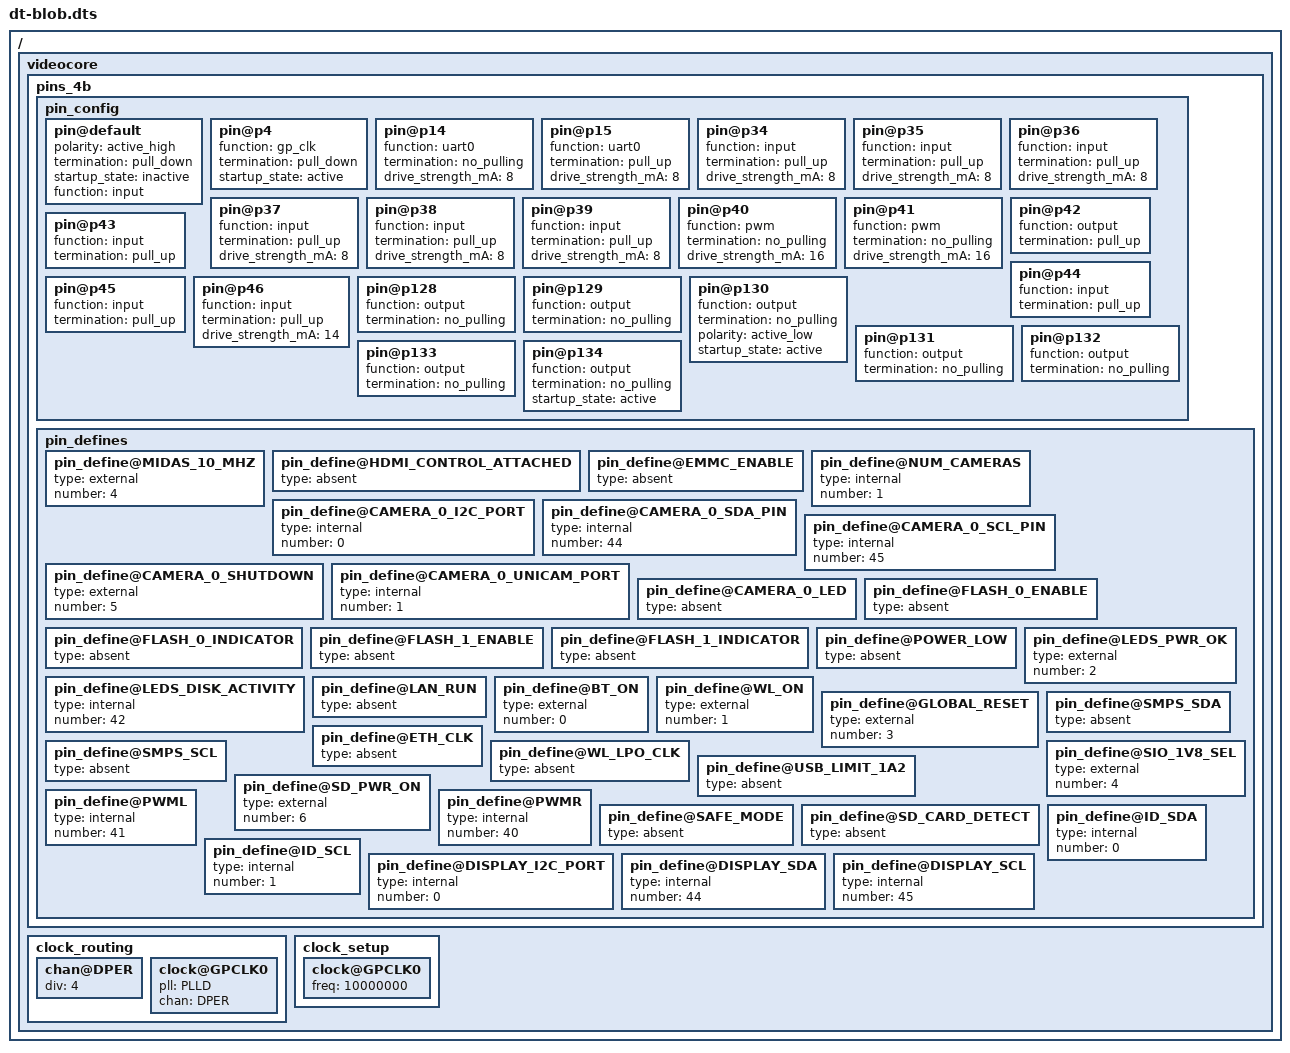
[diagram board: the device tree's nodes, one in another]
/dts-v1/;

/ {
   videocore {
      pins_4b { // Pi4 Model B
         pin_config {
            pin@default {
               polarity = "active_high";
               termination = "pull_down";
               startup_state = "inactive";
               function = "input";
            }; // pin
			pin@p4 { function = "gp_clk"; termination = "pull_down"; startup_state = "active"; }; // MIDAS 10 MHz refclock pin
            pin@p14 { function = "uart0";  termination = "no_pulling"; drive_strength_mA = < 8 >; }; // TX uart0
            pin@p15 { function = "uart0";  termination = "pull_up"; drive_strength_mA = < 8 >; }; // RX uart0
            pin@p34 { function = "input";  termination = "pull_up";    drive_strength_mA = < 8 >; };
            pin@p35 { function = "input";  termination = "pull_up";    drive_strength_mA = < 8 >; };
            pin@p36 { function = "input";  termination = "pull_up";    drive_strength_mA = < 8 >; };
            pin@p37 { function = "input";  termination = "pull_up";    drive_strength_mA = < 8 >; };
            pin@p38 { function = "input";  termination = "pull_up";    drive_strength_mA = < 8 >; };
            pin@p39 { function = "input";  termination = "pull_up";    drive_strength_mA = < 8 >; };
            pin@p40 { function = "pwm";    termination = "no_pulling"; drive_strength_mA = < 16 >; }; // Right audio
            pin@p41 { function = "pwm";    termination = "no_pulling"; drive_strength_mA = < 16 >; }; // Left audio
            pin@p42 { function = "output"; termination = "pull_up"; }; // activity LED
            pin@p43 { function = "input";  termination = "pull_up"; }; // SPIFLASH_CE_N
            pin@p44 { function = "input";  termination = "pull_up"; }; // I2C 0 SDA
            pin@p45 { function = "input";  termination = "pull_up"; }; // I2C 0 SCL
            pin@p46 { function = "input";  termination = "pull_up"; drive_strength_mA = < 14 >; }; // Dummy pin for HSTL drive on bank 2
            pin@p128 { function = "output"; termination = "no_pulling"; }; // BT_ON
            pin@p129 { function = "output"; termination = "no_pulling"; }; // WL_ON
            pin@p130 { function = "output"; termination = "no_pulling"; polarity = "active_low"; startup_state = "active"; }; // PWR_LED (RED)
            pin@p131 { function = "output"; termination = "no_pulling"; }; // GLOBAL_RESET
            pin@p132 { function = "output"; termination = "no_pulling"; }; // SD VDDIO
            pin@p133 { function = "output"; termination = "no_pulling"; }; // Camera shutdown
            pin@p134 { function = "output"; termination = "no_pulling"; startup_state = "active"; }; // SD_PWR_ON
         }; // pin_config

         pin_defines {
			pin_define@MIDAS_10_MHZ{
               type = "external";
			   number = <4>;
            };
            pin_define@HDMI_CONTROL_ATTACHED {
               type = "absent";
            };
            pin_define@EMMC_ENABLE {
               type = "absent";
            };
            pin_define@NUM_CAMERAS {
               type = "internal";
               number = <1>;
            };
            pin_define@CAMERA_0_I2C_PORT {
               type = "internal";
               number = <0>;
            };
            pin_define@CAMERA_0_SDA_PIN {
               type = "internal";
               number = <44>;
            };
            pin_define@CAMERA_0_SCL_PIN {
               type = "internal";
               number = <45>;
            };
            pin_define@CAMERA_0_SHUTDOWN {
               type = "external";
               number = <5>;
            };
            pin_define@CAMERA_0_UNICAM_PORT {
               type = "internal";
               number = <1>;
            };
            pin_define@CAMERA_0_LED {
               type = "absent";
            };
            pin_define@FLASH_0_ENABLE {
               type = "absent";
            };
            pin_define@FLASH_0_INDICATOR {
               type = "absent";
            };
            pin_define@FLASH_1_ENABLE {
               type = "absent";
            };
            pin_define@FLASH_1_INDICATOR {
               type = "absent";
            };
            pin_define@POWER_LOW {
               type = "absent";
            };
            pin_define@LEDS_PWR_OK {
               type = "external";
               number = <2>;
            };
            pin_define@LEDS_DISK_ACTIVITY {
               type = "internal";
               number = <42>;
            };
            pin_define@LAN_RUN {
               type = "absent";
            };
            pin_define@BT_ON {
               type = "external";
               number = <0>;
            };
            pin_define@WL_ON {
               type = "external";
               number = <1>;
            };
            pin_define@GLOBAL_RESET {
               type = "external";
               number = <3>;
            };
            pin_define@SMPS_SDA {
               type = "absent";
            };
            pin_define@SMPS_SCL {
               type = "absent";
            };
            pin_define@ETH_CLK {
               type = "absent";
            };
            pin_define@WL_LPO_CLK {
               type = "absent";
            };
            pin_define@USB_LIMIT_1A2 {
               type = "absent";
            };
            pin_define@SIO_1V8_SEL {
               type = "external";
               number = <4>;
            };
            pin_define@SD_PWR_ON {
               type = "external";
               number = <6>;
            };
            pin_define@PWML {
               type = "internal";
               number = <41>;
            };
            pin_define@PWMR {
               type = "internal";
               number = <40>;
            };
            pin_define@SAFE_MODE {
               type = "absent";
            };
            pin_define@SD_CARD_DETECT {
               type = "absent";
            };
            pin_define@ID_SDA {
               type = "internal";
               number = <0>;
            };
            pin_define@ID_SCL {
               type = "internal";
               number = <1>;
            };
            pin_define@DISPLAY_I2C_PORT {
               type = "internal";
               number = <0>;
            };
            pin_define@DISPLAY_SDA {
               type = "internal";
               number = <44>;
            };
            pin_define@DISPLAY_SCL {
               type = "internal";
               number = <45>;
            };
         }; // pin_defines
      }; // pins
      // MIDAS: 10 MHz clock on GPCLK0
      clock_routing {
	    chan@DPER { div  = <4>; };
		clock@GPCLK0 { pll = "PLLD"; chan = "DPER"; };
      };

      clock_setup {
        clock@GPCLK0 { freq = <10000000>; };
      };
   };
};
